# USB0_VBP2APB_WRAP_CONTROLLER_VBP_CORE_ADDR_MAP register map
Vendor: Texas Instruments
Registers are 32-bit, access per field, reset 0x0 unless marked. A register's access mark holds for its fields unless they carry their own. Offsets are as the file gives them; [hi:lo] are bit positions; {n}, {i} and the like mark numbered series.

## USB0_VBP2APB_WRAP_CONTROLLER_VBP_CORE_ADDR_MAP (part 8 of 9)
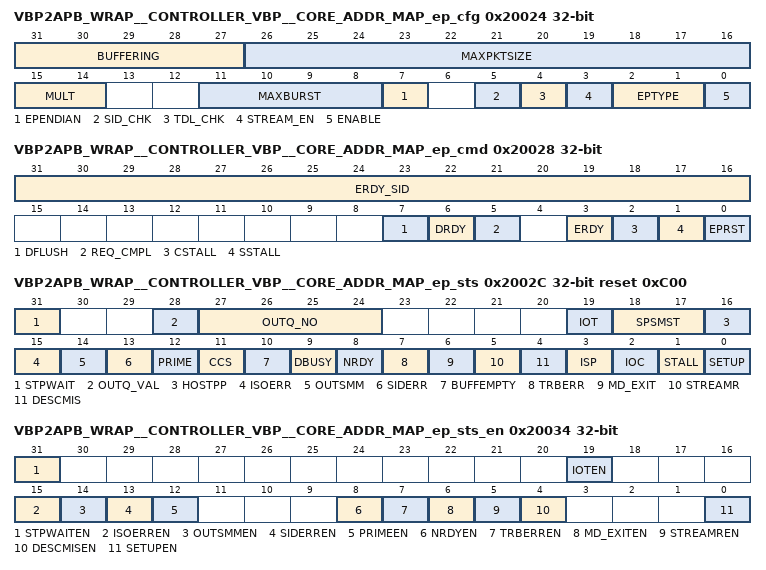
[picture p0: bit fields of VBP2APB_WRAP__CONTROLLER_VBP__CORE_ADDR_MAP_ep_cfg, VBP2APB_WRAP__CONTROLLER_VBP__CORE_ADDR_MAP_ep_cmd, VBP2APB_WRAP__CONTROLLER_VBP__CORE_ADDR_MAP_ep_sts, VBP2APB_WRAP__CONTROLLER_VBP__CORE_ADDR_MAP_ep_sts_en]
0x20024 VBP2APB_WRAP__CONTROLLER_VBP__CORE_ADDR_MAP_ep_cfg — Endpoint Configuration Register The endpoint configuration can be changed only once after reset (or configuration reset: USB_CONF.CFGRST). While the device is not in the CONFIGURED state, each write to EP_CFG register allocates space for endpoint configuration in on-chip memory (this is done automatically by the hardware and invisible to the software). That is why write to this register for one endpoint can be executed only once during setup of the device. When the software finishes the device configuration (i.e. all required endpoints have been enabled), it has to set the USB_CONF.CFGSET bit to inform the hardware that the device is in CONFIGURED state. In this state, writing to EP_CFG register can change only ENABLE, ENDIAN and STREAM_EN bits and does not allocate space for endpoint configuration in on-chip memory. All bytes of the register must be written during endpoint configuration. If all bytes of this register are not written at the same time (e.g. byte access), the MSB must be written at the end of the operation.
  [31:27] BUFFERING rw — Max number of buffered packets. The maximum number of packets the device can buffer in the on-chip memory for a specified endpoint. Valid values are from 0 to 15. Value 0 means that 1 on-chip buffer is available for the appropriate endpoint. Value 15 means that 16 on-chip buffers are available for the appropriate endpoint. Each IN endpoint has individual buffers associated with it. OUT endpoints have common buffers, so buffering for OUT endpoints is determined by the maximum buffering value along all enabled OUT endpoints. The number of possible endpoint buffers depends on the on-chip memory size and the size of endpoint buffers.
  [26:16] MAXPKTSIZE rw — Max packet size. The maximum packet size this endpoint is capable of sending or receiving. SuperSpeed mode: For control endpoints, this field is set to 512. For bulk endpoint types, this field is set to 1024. For interrupt and isochronous endpoints, this field is set to 1024 if this endpoint defines a value in the bMaxBurst field greater than zero. If the value in the bMaxBurst field is set to zero, then this field can have any value from 0 to 1024 for an isochronous endpoint, and 1 to 1024 for an interrupt endpoint. High Speed/Full Speed mode: For control endpoints, this field is set to 64. For other endpoint types this field can have any value from 0 to 1024.
  [15:14] MULT rw — ISO max burst SuperSpeed mode: A zero-based value that indicates the maximum number of bursts within a service interval that this endpoint supports. This field is only valid for isochronous endpoints. A value of zero indicates that the device supports one Burst of bMaxBurst packets per service interval. The max value that can be set in this field in SuperSpeed is '2'. HS/FS mode: This field indicates how many packets will be transferred during micro frame. In Full-Speed mode only one ISO IN packet can be transferred per endpoint, per frame, thus this field has to be always '0'. In High-Speed mode, up to three ISO IN packets can be transferred per endpoint, per microframe, so the max value that can be set in this field in HighSpeed is '2'.
  [11:8] MAXBURST rw — Maximum Burst size. The maximum number of packets the endpoint can send or receive as part of a burst. Valid values are from 0 to 15. A value of 0 indicates that the endpoint can only burst one packet at a time, and a value of 15 indicates that the endpoint can burst up to 16 packets at a time. For endpoints of type control this is set to 0. This field is meaningfull only in SuperSpeed mode.
  [7] EPENDIAN rw — DMA transfer endianness. When the conversion is ON, the byte order within DWORD is inverted. While the bit is set, the software confirms that the transfer length is a multiplication of 4 bytes. Enabling the conversion is possible only when SUPPORT_ENDIANESS_CONV is defined. By default this parameter is not defined, so endianess conversion is disabled. 0: Endianess conversion OFF 1: Endianess conversion ON
  [5] SID_CHK rw — SID check[only in SS mode for BULK OUT EP] This field can be set only for SS bulk OUT endpoints with stream support enabled 1] If SID_CHK bit is set, the device checks whether the incoming packets from the host to the particular OUT endpoint have the SID field set to the expected value. If the packet has an expected SID value is then taken and stored in the on-chip device buffers. If the packet has a different SID than expected, then the packet is rejected [NRDY] and the SIDERROR interrupt is reported to the software. The value of the SID to which incoming packets will be compared, are written to the device during sending ERDY TP [EP_CMD.ERDY and EP_CMD.ERDY_SID]. The SID value from the incoming packet that has been rejected and caused the SIDERR interrupt can be read from the EP_STS_SID register. 2] If SID_CHK bit is not set, then each packet from the host is taken to the on-chip buffers is transmitted by the DMA regardless of the SID field in the TD. 0: SID chceck at device input OFF 1: SID chceck at device input ON
  [4] TDL_CHK rw — TDL check[only in SS mode for BULK OUT EP]. This field has to be set for stream capable SS bulk endpoints and it can be set for other bulk endpoint. The OUT bulk endpoints If the TDL_CHK bit is set if the device takes the packets to the OUT endpoint only when the value of the TDL [EP_CMD.TDL] for this endpoint is different from zero. Each received packet for the particular endpoint decrements the value of a TDL. If the TDL_CHK bit is not set, then each packet from the host to the OUT endpoint is taken as long as it free space in the on-chip device buffers. The IN bulk endpoints This bit is is used by USBSS_DEV to set EOB bit when TDL [programmed value] reach zero. 0: Do not check the TDL value when sending/receiving packets to the endpoints 1: Check the TDL value when sending/receiving packets to the endpoint
  [3] STREAM_EN rw — Stream support enable [only in SS mode]. This bit must be set to enable a stream transfes on a bulk endpoint 0: Stream support OFF 1: Stream support ON
  [2:1] EPTYPE rw — Endpoint type. 0: control, 1: isochronous, 2: bulk, 3: interrupt. Endpoint type is programmable, however, certain types of transmissions require hardware support that must be incorporated prior to implementation. That can be done only for selected endpoints. Selective inclusion of hardware support is to reduce the size of the controller. Accordingly: - Endpoint-type iso should be set by the software only for those endpoints for which isochronous transmission hardware support is enabled. - A bulk endpoint can handle transmission with Bulk Streams support only for those endpoints for which Bulk Stream transmission hardware support is enabled. For detailed description how to implement hardware support for ISO transfers or Bulk Stream transfers see chapter 'Endpoints Implementation'.
  [0] ENABLE rw — Endpoint enable. If endpoint is disabled [the ENABLE bit is cleared], the endpoint will not: - request any interrupts - start any transmission over the DMA Even if Endpoint is disabled, software can set DRDY bit for it, but the DMA transmission will not begin until the endpoint is enabled. 0: disabled 1: enabled Reset value of this bit for EP0 is 1, for other EP's is 0.
0x20028 VBP2APB_WRAP__CONTROLLER_VBP__CORE_ADDR_MAP_ep_cmd access not given — Endpoint Command Register
  [31:16] ERDY_SID rw — ERDY Stream ID value [used in SS mode]. This field contains SID - it will be sent to host in ERDY packet [by writing '1' to ERDY]. This field is meaningfull only in SuperSpeed mode.
  [7] DFLUSH rw — Data flush. Writing '1' to this bit performs the following actions for particular endpoint: - clears DRDY bit and stops DMA transfer - flush endpoint data from on chip buffers As in case of Endpoint reset [EPRST bit], after endpoint data flush the software is responsible for it to re-set the Endpoint TRADDR. When DFLUSH operation is started ['1' is written], CPU must wait until this bit becomes again '0' [it indicates that HW finishes all internal opertations related to DFLUSH], and only then can proceed with next software operations. Writing '0' has no effect.
  [6] DRDY rw — Transfer descriptor ready. Transfer Descriptor Ready for selected endpoint [0 - no effect, 1 - starts transfer]. Writing '1' to this bit informs USBSS-DEV that in-system memory has prepared a new Transfer Descriptor for selected endpoints. If an IN endpoint is 'Not Ready' [NRDY=1 in Endpoint Status Register], then setting the DRDY bit [which is proceeded by DMA transfer to the on-chip buffers] will cause the device to send the ERDY packet. If the TRB error occurs, the DRDY bit is cleared and held in the low state until the TRBERR is not cleared [even if the DTRANS bit is set i.e. the Multiple TRB chain mode is enabled]. This bit is duplicated in the Doorbell register. Writing '1' to this bit while DESCMIS interrupt flag is set for the same endpoint will also clear the DESCMIS flag.
  [5] REQ_CMPL rw — Request complete. 0 : no effect 1 : informs device that Request service is complete Bit valid only for endpoint 0. Writing '1' to this bit informs USBSS-DEV that software finished USB request service and device can send ACK answer for the Status Stage within USB request. This bit is automatically cleared by USBSS-DEV after device answers to the status stage with ACK or STALL. Until software do not set this bit, during proceeding current host request, the device will answer to the status stage with NRDY answer.
  [3] ERDY rw — Send ERDY TP. Writing '1' to this bit forces the device to send ERDY TP with stream ID equal to ERDY_SID. This bit is necessary to support SS bulk stream transfers. This bit is also used during control transfers [in both modes: HS/FS and SS]: writing '1' instruct device controller HW that it can exit from Setup Stage to the Data Stage [or directly to the Status Stage if USB Request is without Data Stage]. However the ERDY packet is only actually sent in SS mode. Writing '0' has no effect.
  [2] CSTALL — Endpoint STALL clear. Writing '1' to this bit cause the endpoint becames not halted. 0: no effect 1: clears endpoint STALL (access R/W1TC)
  [1] SSTALL rw — Endpoint STALL set. Writing '1' to this bit cause the endpoint is halted. 0: no effect 1: STALLs endpoint
  [0] EPRST rw — Endpoint reset. 0: no effect 1: resets endpoint This command performs the following actions for particular endpoint: - clears DRDY bit and stops DMA transfer - clears on-chip buffers - clears sequence number in SS mode or Data Toggle in HS/FS mode This command does not clear Endpoint interrupt if already requested [irq[0] pin was asserted] thus it is recommended first to clear all interrupts from endpoint scheduled to reset. When EPRST operation is started ['1' is written], CPU must wait until this bit becomes again '0' [it indicates that HW finishes all internal opertations related to DFLUSH], and only then can proceed with next software operations. Additionally, when DMA already started processing TD for this EP, the EPRST command cause that DMA engine will once more access the descriptor in external memory. After endpoint reset the software is responsible for it to re-set the Endpoint TRADDR. Writing '0 'has no effect.
0x2002C VBP2APB_WRAP__CONTROLLER_VBP__CORE_ADDR_MAP_ep_sts access not given reset 0xC00 — Endpoint Status Register. The EP_STS register consists of two types of bits: - Interrupt flags (RW1C bits). If any of these bit is active (set to '1') and not masked (with an EP_STS_EN register) then the interrupt is requested (irqs[0] line is set to high). To clear these bits, the software must write a '1' at the apptopriate field. - Status bits (RO bits). These bits are not taken into account for interrupt generation (not reported in EP__ISTS register nor on irqs output), and SW is not expected to clear them
  [31] STPWAIT — Bit used only for EP0. If setup packet is received correctly and stored in the on-chip buffer, this bit is set to 1 and interrupt is generated. Setup packet is applicable only to control transmissions [EP0]. This interrupt can be masked by the corresponding bit in EP_STS_EN register. Writing '1' to this bit clears the interrupt. (access R/W1TC)
  [28] OUTQ_VAL ro — OUT queue valid flag. This field indicates whether the endpoint number of the OUT packet waiting for transmission by the DMA, is valid or not. In other words, whether the packet queue is not empty. As there is one buffers queue for all Out Endpoints, this field is not endpoint related, and thus it can be read regardless of current value stored in the EP_SEL register. 0 - queue of out packets is empty thus OUTQ_NO is not valid 1 - queue of out packets is not empty thus OUTQ_NO is valid This bit is only a status bit [not an interrupt flag].
  [27:24] OUTQ_NO ro — OUT queue endpoint number. This field shows the number of the endpoint to which the packet, received by the host, currently is waiting to be transmitted by the DMA from the on-chip buffers to the system memory. As there is one buffers queue for all Out Endpoints, this field is not endpoint related, and thus it can be read regardless of current value stored in the EP_SEL register. This bit is only a status bit [not an interrupt flag].
  [19] IOT — Interrupt On Transfer complete. This interrupt is generated when the TDL is decremented to zero. It means that the device - does not expect to have more packets from the host [OUT EP] - does not want to send more packets [IN EP] More information can be found in the description of EP_TDL register. Writing '1' to this bit clears the interrupt. (access R/W1TC)
  [18:17] SPSMST ro — Stream Protocol State Machine State [only for Bulk stream endpoints] This field is valid only for stream capable bulk endpoints and reflects the current state of the Stream Protocol State Machine for selected endpoint: 0 - DISABLED 1 - IDLE 2 - START_STREAM 3 - MOVE_DATA Soft should check if the SPSM is in IDLE state before sending ERDY TP from stream EP [leading to the transition from IDE to START_STREAM] Before software will order to send an ERDY TP from stream capable endpoint [leading to the transition from IDLE to START_STREAM] it should first check if the SPSM is in IDLE state. This bit is only a status bit [not an interrupt flag].
  [16] HOSTPP ro — Host Packet Pending [only for SS mode]. Depending on whether the endpoint is enabled for streams or not, this bit behaves as follows: 1]For stream enabled bulk endpoints [EP_CFG.EPSTREAM_EN bit set]: This bit reflects the PP bit in the last packet received from the host during Move Data state of the DOSPSM for the OUT endpoint. This bit is updated on exit from the MOVE DATA state of the DOSPSM and can be analyzed during servicing MD_EXIT interrupt for BULK OUT endpoint with Stream support enabled. If this bit is set to '0' during MD_EXIT interrupt, it means that the host terminated current stream. If this bit is set to '1' during MD_EXIT interrupt, it means that the host doesn't terminated current stream and still has data for this stream. 2]Non stream bulk endpoints [EP_CFG.EPSTREAM_EN bit not set]: This bit reflects the PP bit in the packets received from the host. This bit is updated as long as the EP_CMD.TDL is nonzero and it can be analyzed during servicing IOT interrupt for BULK endpoints. This bit is only a status bit [not an interrupt flag].
  [15] ISOERR — ISO transmission error. Error of isochronous transmission. This bit is set during data transmission to/from ISO endpoints while the last data transfer at PIPE IF is in current micro frame. For ISO IN endpoints: If host asks for data packet and device is not ready for sent data immediatelly, then ISOERR flag is set for particular endpoint and core sends a 0-length DATA packet to the host. The next data portion transfer [for the next micro frame] from system memory to on-chip buffers is automatically started [when EP_CMD.DRDY bit is set or DMA works in DMULT mode]. For ISO OUT endpoints: When host issues an OUT data packet for the specific endpoint but the OUT buffers are full, then device is unable to receive data packet and the ISOERR flag is set. For more information about ISO trasfer see chapter 'Isochronous Transfers'. This interrupt can be masked by the corresponding bit in EP_STS_EN register. Writing '1' to this bit clears the interrupt. (access R/W1TC)
  [14] OUTSMM — OUT size mismatch. This bit is set when host sends a different data size than device was anticipating [according to Data Length field in TRB]. In such a case, the DMA updates length field in current TRB, updates TRADDR [next TRB address], and triggers the interrupt. DMA will not start processing TRB ring of this EP until its DRDY is set. This interrupt can be masked by the corresponding bit in EP_STS_EN register. Writing '1' to this bit clears the interrupt. (access R/W1TC)
  [13] SIDERR — Stream error [used only in SS mode] If host requested IN [sent OUT] packet with particular Stream ID, and device is actually programmed to transfer packets with different Stream ID [SID written in the EP_CMD.ERDY_SID field] the host IN request [OUT packet] is rejected [NRDY] and the SIDERR interrupt is requested. In case of IN direction, the SIDERR interrupt will not be requested when device is not prepared for any transfer [EP_CMD.TDL= 0 for this endpoint]. In this case [and additionally when EP_CMD.DRDY= 0 and EP_STS.DBUSY=0], the DESCMIS interrupt will be requested. This interrupt can be masked by the corresponding bit in EP_STS_EN register. Writing '1' to this bit clears the interrupt. (access R/W1TC)
  [12] PRIME — Prime [used only in SS mode]. This bit is set when the device receives the packet with PRIME ID. This interrupt can be masked by the corresponding bit in EP_STS_EN register. Writing '1' to this bit clears the interrupt. (access R/W1TC)
  [11] CCS ro — Current Cycle Status. Informs about current value of C bit corresponding to DMA ownership of TRBs for selected endpoint. For more information about TRBs C bit see chapter 2.11.3. This bit is only a status bit [not an interrupt flag].
  [10] BUFFEMPTY ro — Endpoint Buffer Empty. When this bit is set to '1', there are no packets for the particular endpoint in the on-chip buffers. This bit is only a status bit [not an interrupt flag].
  [9] DBUSY ro — DMA busy. This bit is set to '1' while the DMA services the endpoint. Through the service means either actual transmission of data between on-chip cache and system memory for particular endpoint or a pending data transmission which has already begun but was interrupted by endpoint with a higher priority. Such pending transmissions will begin automatically themselves after these higher priority. This bit is only a status bit [not an interrupt flag].
  [8] NRDY — Not ready [used only in SS mode]. This bit is automatically set to 1 when for some reason endpoint enters Flow Control. If ERDY is sent automatically by the endpoint [what is done when current TDL value is greater then zero], this interrupt bit is not automatically cleared [although the endpoint itself leaves FlowControl]. Note: For BULK OUT endpoints with TDL_CHK bit seting this interrupt should be used instead of DESCMIS interrupt. See also DESCMIS description. Writing '1' to this bit clears the interrupt. (access R/W1TC)
  [7] TRBERR — TRB error. This bit is set if DMA read corrupted TRB [wrong C bit value or TRB type]. Address of the TRB is stored in the EP_TRADDR register. This interrupt can be masked by the corresponding bit in EP_STS_EN register. If this error occurs, the bit DRDY is cleared and held in the low state until the TRBERR is not cleared. To start the DMA again, the software has to clear this interrupt and set the DRDY bit once more. Writing '1' to this bit clears the interrupt. (access R/W1TC)
  [6] MD_EXIT — EXIT from MOVE DATA State [used only for stream transfers in SS mode] This bit is set to '1' if stream capable endpoint exits from MOVE DATA state of Bulk IN/OUT Stream Ptrotocol State Machine [ISPSM/OSPSM]. Stream support is class-dependent. This interrupt can be masked by the corresponding bit in MD_EXITEN register. Writing '1' to this bit clears the interrupt. (access R/W1TC)
  [5] STREAMR — Stream Rejected [used only in SS mode]. This bit is set to '1' if device tries to initiate stream number and host does not accept it. Stream support is class-dependent. This interrupt can be masked by the corresponding bit in STREAMREN register. Writing '1' to this bit clears the interrupt. (access R/W1TC)
  [4] DESCMIS — Transfer descriptor missing. This bit is set to 1 and interrupt is generated when any of the following conditions are met: - device is requested to send data to host and none of Transfer Descriptor is prepared [IN transfer] - device receives OUT packet and cannot transmit it using DMA as Transfer Descriptor has not been prepared [DRDY was not set] for it [OUT transfer] Note1: This interrupt is not generated for ISO IN endpoints. For such endpoints the ISOERR interrupt should be used. Note2: DMA will not start operating on transfer descriptor array until the OUT packet is received [or host requests IN packet] and processor has not previously notified DMA [by writing to EP_CMD register of DRDY register]. Note2: For BULK OUT endpoints with TDL_CHK bit set this interrupt will not by requested as device will not accept any packet from host when TRB is not prepared [and TDL is not written with non-zero value]. In this case the NRDY interrupt should be used instead of DESMIS. Writing '1' to this bit or writing '1' to EP_CMD.DRDY bit of endpoints which generated interrupt will delete the interrupt. This interrupt can be masked by the corresponding bit in EP_STS_EN register. Writing '1' to this bit clears the interrupt. (access R/W1TC)
  [3] ISP — Interrupt on Short Packet. This bit is set to 1 and interrupt is generated when a transfer containing less data than MaxPacket for a given endpoint has been completed and transfer descriptor has been updated.Enabling or disabling of interrupt is realized by ISP bit in transfer descriptor. Additionally, this interrupt can be masked for a particular endpoint in EP__ISTS register. When in given transfer descriptor both interrupts are enabled [IOC and ISP], then in the case of short packet only one interrupt is generated - SP. Writing '1' to this bit clears the interrupt. (access R/W1TC)
  [2] IOC — Interrupt On Complete When DMA transfer is completed and transfer descriptor is updated, then this bit is set to 1 and interrupt is generated. Enabling or disabling of this interrupt is realized by IOC bit in transfer descriptor. Additionally, this interrupt can be masked for a particular endpoint in EP__ISTS register. When in given transfer descriptor both interrupts [IOC and ISP interrupts] are enabled, then in the case of short packet, only one interrupt is generated - SP. Writing '1' to this bit clears the interrupt. (access R/W1TC)
  [1] STALL ro — Endpoint STALL status 0 - endpoint is not stalled 1 - endpoint is stalled This bit is not treated as an interrupt [not reported in the EP__ISTS register]. This bit is read-only.
  [0] SETUP — Setup transfer complete. Bit used only for EP0. If setup type transmission has been completed and data from host has been received and copied to system memory, this bit is set to '1' and interrupt is generated. Setup packet is applicable only to control transmissions [EP0]. This interrupt can be masked by the corresponding bit in EP_STS_EN register. Writing '1' to this bit clears the interrupt. (access R/W1TC)
0x20030 VBP2APB_WRAP__CONTROLLER_VBP__CORE_ADDR_MAP_ep_sts_sid ro — Endpoint Status Register
  [15:0] SID — Stream ID [used only in SS mode]. Stream ID of packet, which generates interrupt. The interrupts that update the SID field are: - SIDERR for EP OUT - SIDERR/DESCMIS for EP IN For the above interrupts, the values of the SID field reflects: - in case of SIDERR for EP OUT this field reflects the Stream ID of OUT packet sent by host which was rejected by the device, due to SID_CHK bit set - in case of SIDERR/DESCMIS for EP IN this field reflects the Stream ID of ACK TP sent by host which was rejected by the device.
0x20034 VBP2APB_WRAP__CONTROLLER_VBP__CORE_ADDR_MAP_ep_sts_en — Endpoint Status Register Enable
  [31] STPWAITEN rw — Setup Wait interrupt enable. This bit enables the STPWAIT interrupt. Valid only for EP0
  [19] IOTEN rw — Interrupt on Transmission complete enable. This bit enables the IOT interrupt.
  [15] ISOERREN rw — ISO transmission error enable. This bit enables the ISOERR interrupt.
  [14] OUTSMMEN rw — OUT size mismatch enable. This bit enables the OUTSMM interrupt.
  [13] SIDERREN rw — Stream error enable. This bit enables the SIDERR interrupt.
  [12] PRIMEEN rw — Prime enable. This bit enables the PRIME interrupt.
  [8] NRDYEN rw — NRDY enable. This bit enables the NRDY interrupt.
  [7] TRBERREN rw — TRB enable. This bit enables the TRBERR interrupt.
  [6] MD_EXITEN rw — Move Data Exit enable. This bit enables the MD_EXIT interrupt.
  [5] STREAMREN rw — Stream Rejected enable. This bit enables the STREAMR interrupt.
  [4] DESCMISEN rw — OUT transfer missing descriptor enable. This bit enables the DESCMIS interrupt.
  [0] SETUPEN rw — Setup transfer complete. This bit enables the SETUP interrupt. Valid only for EP0.
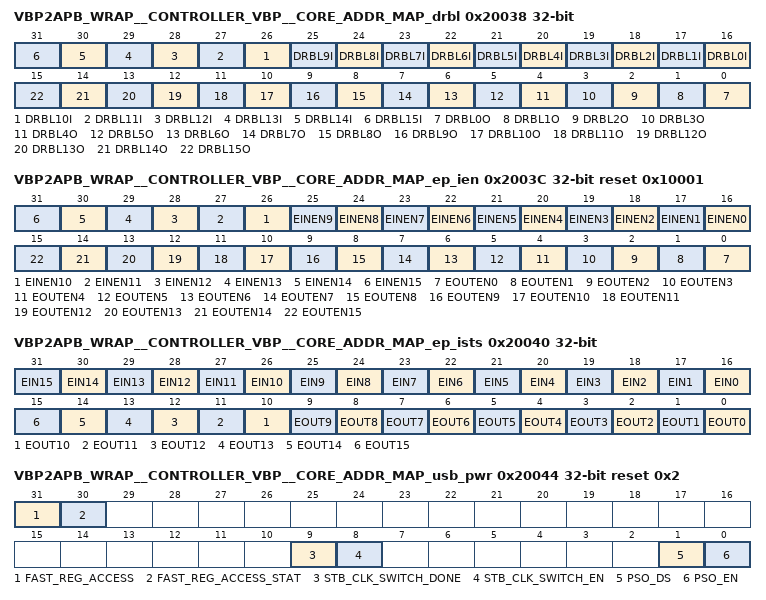
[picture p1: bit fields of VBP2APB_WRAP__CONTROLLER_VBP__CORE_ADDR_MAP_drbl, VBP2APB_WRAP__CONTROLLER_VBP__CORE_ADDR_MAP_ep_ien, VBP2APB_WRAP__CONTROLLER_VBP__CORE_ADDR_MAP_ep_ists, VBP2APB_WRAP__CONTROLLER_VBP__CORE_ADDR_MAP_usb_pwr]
0x20038 VBP2APB_WRAP__CONTROLLER_VBP__CORE_ADDR_MAP_drbl access not given — Doorbell Register - used for initiating transfers with one access to USBSS-DEV, without use of the EP_SEL register(+EP_CMD.DRDY)
  [n+16] DRBL{n}I (n=0..15) — Dorbel Bit - used for initiating transfers for selected Endpoint (access R/W1TS)
  [n] DRBL{n}O (n=0..15) — Dorbel Bit - used for initiating transfers for selected Endpoint (access R/W1TS)
0x2003C VBP2APB_WRAP__CONTROLLER_VBP__CORE_ADDR_MAP_ep_ien rw reset 0x10001 — Endpoints Interrupt Enable Register (1 - enables interrupt, 0 - disables interrupt)
  [n+16] EINEN{n} (n=0..15) — Endpoints Interrupt Enable Bit [1 - enables interrupt, 0 - disables interrupt]
  [n] EOUTEN{n} (n=0..15) — Endpoints Interrupt Enable Bit [1 - enables interrupt, 0 - disables interrupt]
0x20040 VBP2APB_WRAP__CONTROLLER_VBP__CORE_ADDR_MAP_ep_ists ro — Endpoints Interrupt Status Register. The EIN.n/EOUT.n bit corresponds to interrupt request of n-number endpoint. The reason for interrupt can be read from EP_STS. Interrupt remains valid until given EP_STS.n is cleared by writing in the corresponding bit. NOTE: before access to EP_STS register, EP_SEL must be written with appropriate endpoint number
  [n+16] EIN{n} (n=0..15) — Endpoints Interrupt Status Bit.
  [n] EOUT{n} (n=0..15) — Endpoints Interrupt Status Bit.
0x20044 VBP2APB_WRAP__CONTROLLER_VBP__CORE_ADDR_MAP_usb_pwr access not given reset 0x2 — Global power configuration register
  [31] FAST_REG_ACCESS rw — Fast Registers Access. When Device Port is in a low power state [U3/L2/Not Connected], accesses to registers listed in section 2.3 of USBSS-DEV design specification may take long time. In order to enable fast register access in that case, user can use this register in the following way: - set FAST_REG_ACCESS bit - wait until FAST_REG_ACCESS_STAT bit is set - perform required accesses - clear FAST_REG_ACCESS bit Note that to enable USBSS-DEV low power state entry [U3/L2], the FAST_REG_ACCESS bit has to be cleared.
  [30] FAST_REG_ACCESS_STAT ro — Fast Registers Access status. This bit informs if Fast Registers Access is enabled. It should be used as described in FAST_REG_ACCESS bit.
  [9] STB_CLK_SWITCH_DONE ro — Status bit indicating that operation required by STB_CLK_SWITCH_EN write is completed. This bit is optional and implemented only when support for OTG is implemented [indicated by OTG_READY bit set to 1].
  [8] STB_CLK_SWITCH_EN rw — Enables turning-off Reference Clock. This bit is optional and implemented only when support for OTG is implemented [indicated by OTG_READY bit set to 1]. Should not be used when PHY Reference clock control is not supported
  [1] PSO_DS — Power Shut Off capability disable. Writing '1' to this bit disables power domains switching capability and clears the PSO_EN bit. It is recommended to set this bit after during U3EXTI interrupt service. (access R/W1TS)
  [0] PSO_EN — Power Shut Off capability enable. Writing '1' to this bit enables dower domains switching capability and clears the PSO_DS bit. The Domain will be switched off if both PSO_EN will be set and the USB controller will be in the in the U3 state. It is recommended to set this bit in U3ENTI interrupt service, after software ensures that no data transfer is pending. If this bit will be always set, the controller will automatically switch off the power in the switchable PD after USB controller will enter U3 state. (access R/W1TC)
0x20048 VBP2APB_WRAP__CONTROLLER_VBP__CORE_ADDR_MAP_usb_conf2 — USB configuration register 2
  [0] AHB_RETRY_EN rw — AHB retry enable. This bit enables the AHB retrys for AHB slave interface. This bit has no effect when AHB slave interface is not implemented.
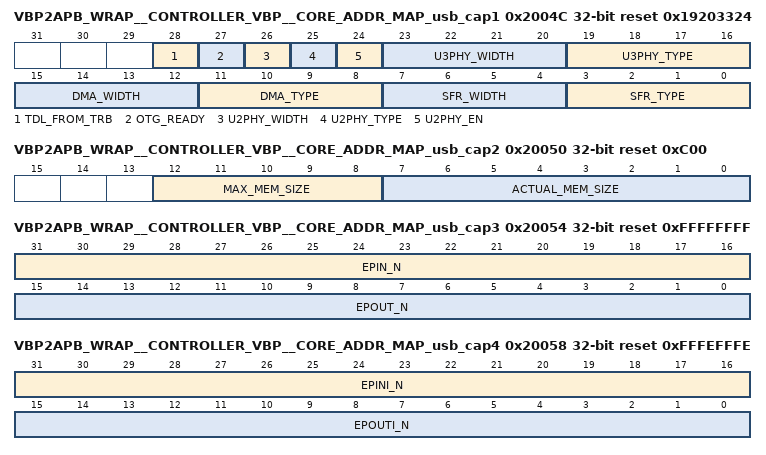
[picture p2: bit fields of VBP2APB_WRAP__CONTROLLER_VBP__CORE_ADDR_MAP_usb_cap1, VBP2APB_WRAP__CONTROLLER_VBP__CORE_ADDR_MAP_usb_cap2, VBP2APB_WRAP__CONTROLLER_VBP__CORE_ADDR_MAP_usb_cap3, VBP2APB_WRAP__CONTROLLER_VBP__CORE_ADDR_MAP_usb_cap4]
0x2004C VBP2APB_WRAP__CONTROLLER_VBP__CORE_ADDR_MAP_usb_cap1 ro reset 0x19203324 — USB Capability Register 1
  [28] TDL_FROM_TRB — This field informs if device controller supports automatic internal TDL calculation basing on the size provided in TRB for DMULT mode: - 0 - controller doesn't support automatic internal TDL calculation - 1 - controller supports automatic internal TDL calculation
  [27] OTG_READY — This field informs if device is OTG ready: - pure device mode: 0x0, - some features and ports for CDNS USB OTG controller are implemented: 0x1.
  [26] U2PHY_WIDTH — USB2 PHY Interface width. This field reflects width of USB2 PHY interface implemented: - 8 bit interface: 0x0, - 16 bit interface: 0x1. Note: The ULPI interface is always 8-bit wide.
  [25] U2PHY_TYPE — USB2 PHY Interface type. This field reflects type of USB2 PHY interface implemented: - UTMI: 0x0, - ULPI: 0x1.
  [24] U2PHY_EN — USB2 PHY Interface enable. This field informs if USB2 PHY interface is implemented: - interface NOT implemented: 0x0, - interface implemented: 0x1.
  [23:20] U3PHY_WIDTH — USB3 PHY Interface width. This field reflects width of USB3 PHY interface implemented: - 0x0: 8 bit PIPE interface, - 0x1: 16 bit PIPE interface, - 0x2: 32 bit PIPE interface, - 0x3: 64 bit PIPE interface, - 0x4-0xF: reserved. Note: When SSIC interface is implemented this field shows the width of internal PIPE interface. The RMMI interface is always 20-bit wide.
  [19:16] U3PHY_TYPE — USB3 PHY Interface type. This field reflects type of USB3 PHY interface implemented: - 0x0: USB PIPE, - 0x1: RMMI, - 0x2-0xF: reserved
  [15:12] DMA_WIDTH — DMA Interface width. This field reflects width of DMA interface implemented: - 0x0: reserved, - 0x1: reserved, - 0x2: 32 bit interface, - 0x3: 64 bit interface, - 0x4-0xF: reserved
  [11:8] DMA_TYPE — DMA Interface type. This field reflects type of DMA interface implemented: - 0x0: OCP, - 0x1: AHB, - 0x2: PLB, - 0x3: AXI, - 0x4-0xF: reserved
  [7:4] SFR_WIDTH — SFR Interface width. This field reflects width of SFR interface implemented: - 0x0: 8 bit interface, - 0x1: 16 bit interface, - 0x2: 32 bit interface, - 0x3: 64 bit interface, - 0x4-0xF: reserved
  [3:0] SFR_TYPE — SFR Interface type. This field reflects type of SFR interface implemented: 0x0 - OCP, 0x1 - AHB, 0x2 - PLB, 0x3 - AXI, 0x4 - APB, 0x5-0xF - reserved.
0x20050 VBP2APB_WRAP__CONTROLLER_VBP__CORE_ADDR_MAP_usb_cap2 ro reset 0xC00 — USB Capability Register
  [12:8] MAX_MEM_SIZE — Max supported mem size. This field reflects width of on-chip RAM address bus width, which determines max supported mem size: 0x0-0x7 reserved, 0x8 - support for 4kB mem, 0x9 - support for 8kB mem, 0xA - support for 16kB mem, 0xB - support for 32kB mem, 0xC - support for 64kB mem, 0xD - support for 128kB mem, 0xE - support for 256kB mem, 0xF - reserved.
  [7:0] ACTUAL_MEM_SIZE — The actual size of the connected On-chip RAM memory in kB: - 0 means 256 kB [max supported mem size] - value other than 0 reflects the mem size in kB. This value reflects the CDNS_USBSSDEV_ATTACHED_MEM_SIZE parameter defined in the usbss_dev_defines.v file. This value has to be adequately set before synthesis by engineer who connects the on-chip memory for controller.
0x20054 VBP2APB_WRAP__CONTROLLER_VBP__CORE_ADDR_MAP_usb_cap3 ro reset 0xFFFFFFFF — USB Capability Register 3. Implemented Endpoints. EPIN.n/EPOUT.n bit informs if n-number endpoint is implemented in the hardware. Default: all EP
  [31:16] EPIN_N — Endpoints IN
  [15:0] EPOUT_N — Endpoints OUT
0x20058 VBP2APB_WRAP__CONTROLLER_VBP__CORE_ADDR_MAP_usb_cap4 ro reset 0xFFFEFFFE — ISO HW support for Endpoints implemented EPINI.n/EPOUTI.n bit informs if n- number endpoint has ISO support implemented in the hardware. Note that EP0 is not intended for isochronous transfers, so both EPINI.0 and EPOUTI.0 must be always set to 0.
  [31:16] EPINI_N — Endpoints IN
  [15:0] EPOUTI_N — Endpoints OUT
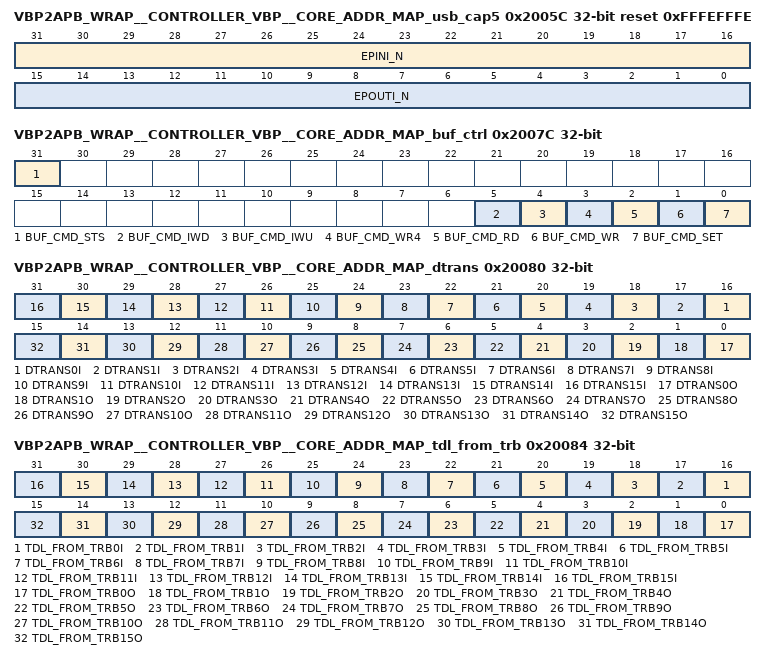
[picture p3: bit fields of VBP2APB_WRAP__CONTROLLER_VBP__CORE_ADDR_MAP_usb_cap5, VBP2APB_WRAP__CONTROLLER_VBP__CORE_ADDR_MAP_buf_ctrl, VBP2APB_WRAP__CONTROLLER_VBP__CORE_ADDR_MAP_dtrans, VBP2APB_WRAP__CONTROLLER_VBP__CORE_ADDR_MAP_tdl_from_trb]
0x2005C VBP2APB_WRAP__CONTROLLER_VBP__CORE_ADDR_MAP_usb_cap5 ro reset 0xFFFEFFFE — Bulk Stream HW support for Endpoints implemented. EPINS.n/EPOUTS.n bit informs if n-number endpoint has Bulk Stream support implemented in the hardware. Note that EP0 is not intended for stream transfers, so both EPINS.0 and EPOUTS.0 must be always set to '0'.
  [31:16] EPINI_N — Endpoints IN
  [15:0] EPOUTI_N — Endpoints OUT
0x20060 VBP2APB_WRAP__CONTROLLER_VBP__CORE_ADDR_MAP_usb_cap6 ro reset 0x2450D — Device controller version.
  [31:0] VERSION
{0x20060+4i} VBP2APB_WRAP__CONTROLLER_VBP__CORE_ADDR_MAP_usb_cpkt{i} rw (i=1..3) — Custom Packet value. If the USB_CMD.SPKT bit is set, then this field is sent to the host as DWORD {i-1} in the Transaction Packet. Refer to USB3.0 specification, chapter 8.5 Transaction Packet for more details. This field must be filled up before the USB_CMD.SPKT bit is set, and cannot be changed while USB_CMD.SPKT bit is not zero (TP is being sent by the device controller)
  [31:0] CPKT{i} — Custom Packet value {i}.
0x20070 VBP2APB_WRAP__CONTROLLER_VBP__CORE_ADDR_MAP_ep_dma_ext_addr — Upper address for DMA This register is optional and is implemented only if the DMA supports address bigger than 32-bit address
  [15:0] EP_DMA_ADDR_H rw — Transfer Ring address. This register specify upper [above 32-bits] DMA address for each endpoint separatelly. This part of DMA address, is not modified by the DMA. CPU can use this register [read it or write to it] only when endpoint is selected [using EP_SEL register]
0x20074 VBP2APB_WRAP__CONTROLLER_VBP__CORE_ADDR_MAP_buf_addr rw — Address for On-chip Buffer operations. Used for accessing device controller on-chip memory via SFR interface. This register is used together with BUF_DATA and BUF_CTRL registers.
  [31:0] BUF_ADDR — On-chip Memory Address. This register specify the address of the on-chip memory cell which is accessed using BUF_CTRL register.
0x20078 VBP2APB_WRAP__CONTROLLER_VBP__CORE_ADDR_MAP_buf_data rw — Data for On-chip Buffer operations. Used for accessing device controller on-chip memory via SFR interface. This register is used together with BUF_ADDR and BUF_CTRL registers.
  [31:0] BUF_DATA — Data for On-chip Buffer operations. This register specify the address of the on-chip memory cell which is accessed using BUF_CTRL register. For write operation this register must be written before WRITE command is issued using BUF_CTRL register. For read operation, this register must be read after READ command is issued using BUF_CTRL register.
0x2007C VBP2APB_WRAP__CONTROLLER_VBP__CORE_ADDR_MAP_buf_ctrl — On-chip Buffer Access register. Used for accessing device controller on-chip memory via SFR interface. This register is used together with BUF_ADDR and BUF_DATA registers.
  [31] BUF_CMD_STS ro — Status of BUF_CMD operations. This bit is set high when controller performs BUF CMD IWD and IWU operations. When it is set, no other SFR or DMA operation can be issued to the controller.
  [5] BUF_CMD_IWD rw — Incremental write counting down to device on-chip mem. Used for incremental writing data into device on-chip memory starting from address pointed by BUF_ADDR register [two lsb rounded down to 0]. To write data to memory, the following order must be maintained: 1] BUF_ADDR register must be set with start address, 2] The BUF_DATA must be set with data expected to be written to on-chip mem 3] BUF_CMD_IWD with BUF_CMD_SET must be set to perform write operation. This write operation is effective only when this BUF_CMD_IWD bit is set together with the BUF_CMD_SET bit. As long as controller performs this command, the BUF_CMD_STS status bit is set, and no other SFR or DMA operation can be issued to the controller. This command can be useful during memory initialization
  [4] BUF_CMD_IWU rw — Incremental write counting up to device on-chip mem. Used for incremental writing data into device on-chip memory starting from address pointed by BUF_ADDR register [two lsb rounded down to 0]. To write data to memory, the following order must be maintained: 1] BUF_ADDR register must be set with start address, 2] The BUF_DATA must be set with data expected to be written to on-chip mem 3] BUF_CMD_IWD with BUF_CMD_SET must be set to perform write operation. This write operation is effective only when this BUF_CMD_IWU bit is set together with the BUF_CMD_SET bit. As long as controller performs this command, the BUF_CMD_STS status bit is set, and no other SFR or DMA operation can be issued to the controller. This command can be useful during memory initialization
  [3] BUF_CMD_WR4 rw — Write 4 words [16B] to device on-chip mem. Used for writing 4 words [4x duplicated BUF_DATA data] into device on-chip memory at address pointed by BUF_ADDR register [two lsb rounded down to 0]. To write data to memory, the following order must be maintained: 1] BUF_ADDR register must be set with address to be accessed, 2] The BUF_DATA must be set with data expected to be written to on-chip mem 3] BUF_CMD_WR4 with BUF_CMD_SET must be set to perform write operation. During this operation the BUF_DATA [duplicated 4 times] register is written to memory. This write operation is effective only when this BUF_CMD_WR4 bit is set together with the BUF_CMD_SET bit. This command can be useful during memory initialization
  [2] BUF_CMD_RD rw — Read data [32B] from device on-chip mem. Used for reading data [1 word] from device on-chip memory from address pointed by BUF_ADDR register. To read data from memory,the following order must be maintained: 1] BUF_ADDR register must be set with address to be accessed, 2] BUF_CMD_RD with BUF_CMD_SET must be set to perform read operation. During this operation the BUF_DATA register is loaded with data readed from memory 3] The BUF_DATA can be read. This read operation is effective only when this BUF_CMD_RD bit is set together with the BUF_CMD_SET bit.
  [1] BUF_CMD_WR rw — Write 1 word [4B] to device on-chip mem. Used for writing 1 word [as prepared in BUF_DATA register] into device on-chip memory at address pointed by BUF_ADDR register. To write data to memory,the following order must be maintained: 1] BUF_ADDR register must be set with address to be accessed, 2] The BUF_DATA must be set with data expected to be written to on-chip mem 3] BUF_CMD_WR with BUF_CMD_SET must be set to perform write operation. During this operation the BUF_DATA register is written to memory. This write operation is effective only when this BUF_CMD_WR bit is set together with the BUF_CMD_SET bit.
  [0] BUF_CMD_SET rw — Buffer Command Set. This bit must be written 1 in conjuction with one of WR, RD, WR4 IWD or IWU commands to make command effective. Only one command can be set at a moment. Commands WR, WR4 and RD are executed immediatelly, but after issuing commands IWD and IWU, the BUF_CMD_STS bit must be check before going forward to other SW operations
0x20080 VBP2APB_WRAP__CONTROLLER_VBP__CORE_ADDR_MAP_dtrans rw — DMA transfer configuration Register (1 - DMULT mode, 0 - DSINGLE mode). Bits 0..15 applies to EPOUT0..EPOUT15 and bits 16..31 applies to EPIN0..EPIN15
  [n+16] DTRANS{n}I (n=0..15) — DMA transfer configuration status for selected Endpoint[0 - single request - Single TRB chain. Single request [DRDY/Doorbell] triggers DMA, which transfers single TRB chain only and ends the EP transfer. 1 - single request - Multiple TRB chain. Single request [DRDY/Doorbell] triggers DMA which starts transfer until the owner of the new chain is not DMA [this causes a TRB error interrupt]. ]
  [n] DTRANS{n}O (n=0..15) — DMA transfer configuration status for selected Endpoint[0 - single request - Single TRB chain. Single request [DRDY/Doorbell] triggers DMA, which transfers single TRB chain only and ends the EP transfer. 1 - single request - Multiple TRB chain. Single request [DRDY/Doorbell] triggers DMA which starts transfer until the owner of the new chain is not DMA [this causes a TRB error interrupt]. ]
0x20084 VBP2APB_WRAP__CONTROLLER_VBP__CORE_ADDR_MAP_tdl_from_trb rw — Source of TDL configuration Register (1 - TDL read by DMA from TD_SIZE field in TRB , 0 - TDL programmed through EP_TDL register). Bits 0..15 applies to EPOUT0..EPOUT15 and bits 16..31 applies to EPIN0..EPIN15
  [n+16] TDL_FROM_TRB{n}I (n=0..15) — This field informs if support for automatic internal TDL calculation basing on the size provided in TRB for DMULT mode is enabled for selected Endpoint. To enable/disable this feature use the ENABLE_TDL_TRB/DISABLE_TDL_TRB bits in the USB_CONF2 register. When this option is enabled the TDL programming with EP_CMD.TDL+STDL is disabled, however read operation through this register can be performed. - 0 - controller doesn't support automatic internal TDL calculation - 1 - controller supports automatic internal TDL calculation This feature can be enabled only when controller supports it, i.e. when the USB_CAP1.TDL_FROM_TRB=1 and when DMULT mode for particular EP is set
  [n] TDL_FROM_TRB{n}O (n=0..15) — This field informs if support for automatic internal TDL calculation basing on the size provided in TRB for DMULT mode is enabled for selected Endpoint. To enable/disable this feature use the ENABLE_TDL_TRB/DISABLE_TDL_TRB bits in the USB_CONF2 register. When this option is enabled the TDL programming with EP_CMD.TDL+STDL is disabled, however read operation through this register can be performed. - 0 - controller doesn't support automatic internal TDL calculation - 1 - controller supports automatic internal TDL calculation This feature can be enabled only when controller supports it, i.e. when the USB_CAP1.TDL_FROM_TRB=1 and when DMULT mode for particular EP is set
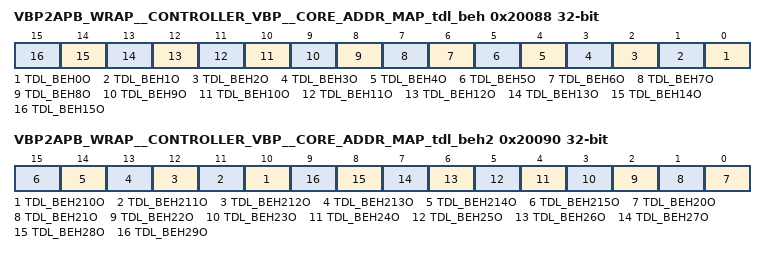
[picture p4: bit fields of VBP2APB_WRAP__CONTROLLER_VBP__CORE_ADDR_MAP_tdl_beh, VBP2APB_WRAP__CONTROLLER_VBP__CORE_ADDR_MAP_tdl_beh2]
0x20088 VBP2APB_WRAP__CONTROLLER_VBP__CORE_ADDR_MAP_tdl_beh access not given — TDL behavior configuration Register. Value 0 means that USB short packet decrements TDL, value 1 means that USB short packet clears-blocks TDL (defined by TDL_BEH2 register). When specific Endpoint works in TDL_FROM_TRB mode (TDL_FROM_TRB.n == 1) this register must be set to 1. When specific Endpoint is configured to Bulk stream transfers (EP_CFG.STREAM_EN == 1) this register must be set to 0. Bits 0..15 applies to EPOUT0..EPOUT15
  [n] TDL_BEH{n}O rw (n=0..15) — TDL behavior configuration Bit. This register configures TDL behavior for selected Endpoint.
0x2008C VBP2APB_WRAP__CONTROLLER_VBP__CORE_ADDR_MAP_ep_tdl — Endpoint TDL Register
  [10:0] TDL rw — This field can be used to update/read internal TDL counter when TDL_FROM_TRB mode is not enabled for specific Endpoint.Writing into this field any non-zero value, will result in adding to existing TDL value the new written value. A as the maximum accumulative value of TDL counter is 2047, so when new value is written, and a sum of existing value and new value exceeds 2047, then register is wrap around, e.g. adding value 10 to the existing 2040 will result a value 2 in the TDL register. Writing zero, reset TDL counter to zero. For more information see USBSS-DEV_design_specification document.
0x20090 VBP2APB_WRAP__CONTROLLER_VBP__CORE_ADDR_MAP_tdl_beh2 access not given — TDL behavior 2 configuration Register. Value 0 means that USB short packet temporary gates TDL for protocol, allowing SW to read curent value of TDL. After SW reads TDL (on IOT irq) it should clear TDL to remove gating TDL value for protocol, value 1 means that USB short packet immediatelly clears TDL. When specific Endpoint works in TDL_FROM_TRB mode (TDL_FROM_TRB.n == 1) this register must be set to 1. When specific Endpoint is configured to Bulk stream transfers (EP_CFG.STREAM_EN == 1) this register must be set to 0. Bits 0..15 applies to EPOUT0..EPOUT15
  [n-200] TDL_BEH{n}O rw (n=210..215) — TDL behavior 2 configuration Bit. This register configures TDL behavior for selected Endpoint.
  [n-20] TDL_BEH{n}O rw (n=20..29) — TDL behavior 2 configuration Bit. This register configures TDL behavior for selected Endpoint.
